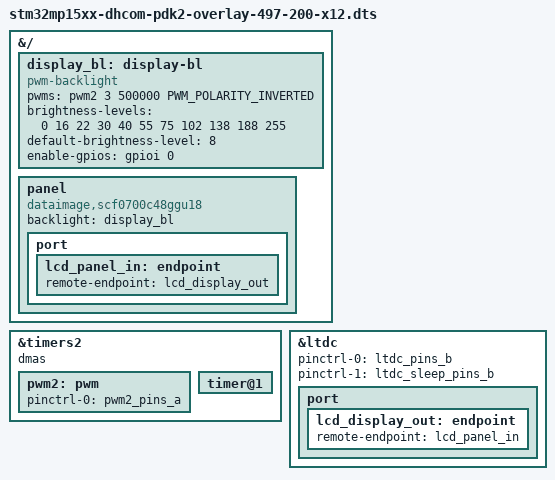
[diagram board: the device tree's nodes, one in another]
// SPDX-License-Identifier: (GPL-2.0+ OR BSD-3-Clause)
/*
 * Copyright (C) 2020 Marek Vasut <marex@denx.de>
 */
#include <dt-bindings/gpio/gpio.h>
#include <dt-bindings/interrupt-controller/arm-gic.h>
#include <dt-bindings/pwm/pwm.h>

/dts-v1/;
/plugin/;

&{/} {
	#address-cells = <1>;
	#size-cells = <1>;

	display_bl: display-bl {
		compatible = "pwm-backlight";
		pwms = <&pwm2 3 500000 PWM_POLARITY_INVERTED>;
		brightness-levels = <0 16 22 30 40 55 75 102 138 188 255>;
		default-brightness-level = <8>;
		enable-gpios = <&gpioi 0 GPIO_ACTIVE_HIGH>;
		status = "okay";
	};

	panel {
		compatible = "dataimage,scf0700c48ggu18";
		backlight = <&display_bl>;

		port {
			lcd_panel_in: endpoint {
				remote-endpoint = <&lcd_display_out>;
			};
		};
	};
};

&timers2 {
	/* spare dmas for other usage (un-delete to enable pwm capture) */
	dmas;
	dma-names;
	status = "okay";

	pwm2: pwm {
		#pwm-cells = <3>;
		pinctrl-0 = <&pwm2_pins_a>;
		pinctrl-names = "default";
		status = "okay";
	};

	timer@1 {
		status = "okay";
	};
};

&ltdc {
	pinctrl-names = "default", "sleep";
	pinctrl-0 = <&ltdc_pins_b>;
	pinctrl-1 = <&ltdc_sleep_pins_b>;
	status = "okay";

	port {
		lcd_display_out: endpoint {
			remote-endpoint = <&lcd_panel_in>;
		};
	};
};
